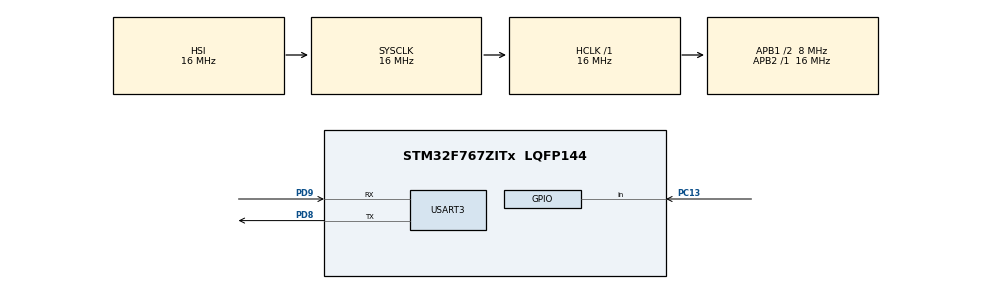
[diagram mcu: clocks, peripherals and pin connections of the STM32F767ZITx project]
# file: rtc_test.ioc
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Mcu.Family=STM32F7
Mcu.Name=STM32F767ZITx
Mcu.Package=LQFP144
NVIC.PriorityGroup=NVIC_PRIORITYGROUP_4
PC13.Signal=GPIO_Input
PC14/OSC32_IN.Mode=LSE-External-Oscillator
PC14/OSC32_IN.Signal=RCC_OSC32_IN
PC15/OSC32_OUT.Mode=LSE-External-Oscillator
PC15/OSC32_OUT.Signal=RCC_OSC32_OUT
PD8.Mode=Asynchronous
PD8.Signal=USART3_TX
PD9.Mode=Asynchronous
PD9.Signal=USART3_RX
ProjectManager.HeapSize=0x200
ProjectManager.StackSize=0x400
ProjectManager.TargetToolchain=MDK-ARM V5
RCC.48MHZClocksFreq_Value=24000000
RCC.AHBFreq_Value=16000000
RCC.APB1CLKDivider=RCC_HCLK_DIV2
RCC.APB1Freq_Value=8000000
RCC.APB1TimFreq_Value=16000000
RCC.APB2Freq_Value=16000000
RCC.APB2TimFreq_Value=16000000
RCC.CortexFreq_Value=16000000
RCC.HCLKFreq_Value=16000000
RCC.HSE_VALUE=16000000
RCC.HSI_VALUE=16000000
RCC.PLLMUL=RCC_PLL_MUL9
RCC.PRESCALERUSB=RCC_USBCLKSOURCE_PLL_DIV1_5
RCC.RTCClockSelection=RCC_RTCCLKSOURCE_LSE
RCC.SYSCLKFreq_VALUE=16000000
RCC.SYSCLKSourceVirtual=RCC_SYSCLKSOURCE_PLLCLK
RCC.USBFreq_Value=96000000
RCC.VCOOutputFreq_Value=192000000
USART3.VirtualMode-Asynchronous=VM_ASYNC
VP_RTC_VS_RTC_Activate.Mode=RTC_Enabled
board=NUCLEO-F767ZI

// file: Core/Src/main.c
/* USER CODE BEGIN Header */
/**
  ******************************************************************************
  * @file           : main.c
  * @brief          : Main program body
  ******************************************************************************
  * @attention
  *
  * <h2><center>&copy; Copyright (c) 2019 STMicroelectronics.
  * All rights reserved.</center></h2>
  *
  * This software component is licensed by ST under BSD 3-Clause license,
  * the "License"; You may not use this file except in compliance with the
  * License. You may obtain a copy of the License at:
  *                        opensource.org/licenses/BSD-3-Clause
  *
  ******************************************************************************
  */
/* USER CODE END Header */

#include "main.h"
#include "rtc.h"
#include "usart.h"
#include "gpio.h"

/* USER CODE BEGIN Includes */
#include "stdio.h"
#include "stdlib.h"
/* USER CODE END Includes */

void SystemClock_Config(void);

int main(void)
{

  /* MCU Configuration--------------------------------------------------------*/

  /* Reset of all peripherals, Initializes the Flash interface and the Systick. */
  HAL_Init();

  /* Configure the system clock */
  SystemClock_Config();

  /* Initialize all configured peripherals */
  MX_GPIO_Init();
  MX_RTC_Init();
  MX_USART3_UART_Init();
  /* USER CODE BEGIN 2 */

	RTC_TimeTypeDef sTime;
	RTC_DateTypeDef sDate;

	printf("%d hours %d minutes %d seconds, day:%d month %d year%d; dayOfWeek: %d \r\n",
		sTime.Hours, sTime.Minutes, sTime.Seconds, sDate.Date, sDate.Month, sDate.Year, sDate.WeekDay);

	if(HAL_GPIO_ReadPin(GPIOC,GPIO_PIN_13)) //if user buttos is pressed set time/date
	{
		//1) Set time
		sTime.Hours = 23;
		sTime.Minutes = 59;
		sTime.Seconds = 45;
		HAL_RTC_SetTime(&hrtc, &sTime, RTC_FORMAT_BIN);
		//2) Set date
		sDate.Date = 31;
		sDate.Month = RTC_MONTH_DECEMBER;
		//sDate.WeekDay = RTC_WEEKDAY_SUNDAY;
		sDate.Year = 17;
		HAL_RTC_SetDate(&hrtc, &sDate, RTC_FORMAT_BIN);
	}

  /* USER CODE END 2 */

  /* Infinite loop */
  /* USER CODE BEGIN WHILE */
  while (1)
  {
		//HAL_StatusTypeDef HAL_RTC_SetTime(RTC_HandleTypeDef *hrtc, RTC_TimeTypeDef *sTime, uint32_t Format);
		//HAL_StatusTypeDef HAL_RTC_GetTime(RTC_HandleTypeDef *hrtc, RTC_TimeTypeDef *sTime, uint32_t Format);
		//HAL_StatusTypeDef HAL_RTC_SetDate(RTC_HandleTypeDef *hrtc, RTC_DateTypeDef *sDate, uint32_t Format);
		//HAL_StatusTypeDef HAL_RTC_GetDate(RTC_HandleTypeDef *hrtc, RTC_DateTypeDef *sDate, uint32_t Format);

		HAL_Delay(1000);

		HAL_RTC_GetTime(&hrtc, &sTime, RTC_FORMAT_BIN);
		HAL_RTC_GetDate(&hrtc, &sDate, RTC_FORMAT_BIN);
		printf("%d hours %d minutes %d seconds, day:%d month %d year%d; dayOfWeek: %d \r\n",
			sTime.Hours, sTime.Minutes, sTime.Seconds, sDate.Date, sDate.Month, sDate.Year, sDate.WeekDay);

    /* USER CODE END WHILE */

  }
}

void SystemClock_Config(void)
{
  RCC_OscInitTypeDef RCC_OscInitStruct = {0};
  RCC_ClkInitTypeDef RCC_ClkInitStruct = {0};
  RCC_PeriphCLKInitTypeDef PeriphClkInitStruct = {0};

  /** Configure LSE Drive Capability
  */
  HAL_PWR_EnableBkUpAccess();
  __HAL_RCC_LSEDRIVE_CONFIG(RCC_LSEDRIVE_LOW);
  /** Configure the main internal regulator output voltage
  */
  __HAL_RCC_PWR_CLK_ENABLE();
  __HAL_PWR_VOLTAGESCALING_CONFIG(PWR_REGULATOR_VOLTAGE_SCALE3);
  /** Initializes the CPU, AHB and APB busses clocks
  */
  RCC_OscInitStruct.OscillatorType = RCC_OSCILLATORTYPE_HSI|RCC_OSCILLATORTYPE_LSE;
  RCC_OscInitStruct.LSEState = RCC_LSE_ON;
  RCC_OscInitStruct.HSIState = RCC_HSI_ON;
  RCC_OscInitStruct.HSICalibrationValue = RCC_HSICALIBRATION_DEFAULT;
  RCC_OscInitStruct.PLL.PLLState = RCC_PLL_NONE;
  if (HAL_RCC_OscConfig(&RCC_OscInitStruct) != HAL_OK)
  {
    Error_Handler();
  }
  /** Initializes the CPU, AHB and APB busses clocks
  */
  RCC_ClkInitStruct.ClockType = RCC_CLOCKTYPE_HCLK|RCC_CLOCKTYPE_SYSCLK
                              |RCC_CLOCKTYPE_PCLK1|RCC_CLOCKTYPE_PCLK2;
  RCC_ClkInitStruct.SYSCLKSource = RCC_SYSCLKSOURCE_HSI;
  RCC_ClkInitStruct.AHBCLKDivider = RCC_SYSCLK_DIV1;
  RCC_ClkInitStruct.APB1CLKDivider = RCC_HCLK_DIV2;
  RCC_ClkInitStruct.APB2CLKDivider = RCC_HCLK_DIV1;

  if (HAL_RCC_ClockConfig(&RCC_ClkInitStruct, FLASH_LATENCY_0) != HAL_OK)
  {
    Error_Handler();
  }
  PeriphClkInitStruct.PeriphClockSelection = RCC_PERIPHCLK_RTC|RCC_PERIPHCLK_USART3;
  PeriphClkInitStruct.RTCClockSelection = RCC_RTCCLKSOURCE_LSE;
  PeriphClkInitStruct.Usart3ClockSelection = RCC_USART3CLKSOURCE_PCLK1;
  if (HAL_RCCEx_PeriphCLKConfig(&PeriphClkInitStruct) != HAL_OK)
  {
    Error_Handler();
  }
}

void Error_Handler(void)
{
}

/************************ (C) COPYRIGHT STMicroelectronics *****END OF FILE****/
